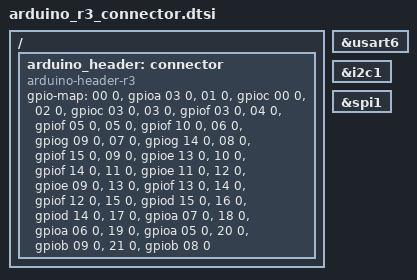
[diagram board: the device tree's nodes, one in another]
/*
 * Copyright (c) 2019 Linaro Limited
 * Copyright (c) 2019 Peter Nimac
 *
 * SPDX-License-Identifier: Apache-2.0
 */

/ {
	arduino_header: connector {
		compatible = "arduino-header-r3";
		#gpio-cells = <2>;
		gpio-map = <00 0 &gpioa 03 0>,	/* A0 */
				   <01 0 &gpioc 00 0>,	/* A1 */
				   <02 0 &gpioc 03 0>,	/* A2 */
				   <03 0 &gpiof 03 0>,	/* A3 */
				   <04 0 &gpiof 05 0>,	/* A4 */
				   <05 0 &gpiof 10 0>,	/* A5 */
				   <06 0 &gpiog 09 0>,	/* D0 */
				   <07 0 &gpiog 14 0>,	/* D1 */
				   <08 0 &gpiof 15 0>,	/* D2 */
				   <09 0 &gpioe 13 0>,	/* D3 */
				   <10 0 &gpiof 14 0>,	/* D4 */
				   <11 0 &gpioe 11 0>,	/* D5 */
				   <12 0 &gpioe 09 0>,	/* D6 */
				   <13 0 &gpiof 13 0>,	/* D7 */
				   <14 0 &gpiof 12 0>,	/* D8 */
				   <15 0 &gpiod 15 0>,	/* D9 */
				   <16 0 &gpiod 14 0>,	/* D10 */
				   <17 0 &gpioa 07 0>,	/* D11 */
				   <18 0 &gpioa 06 0>,	/* D12 */
				   <19 0 &gpioa 05 0>,	/* D13 */
				   <20 0 &gpiob 09 0>,	/* D14 */
				   <21 0 &gpiob 08 0>;	/* D15 */
	};
};

arduino_serial: &usart6 {};
arduino_i2c: &i2c1 {};
arduino_spi: &spi1 {};
